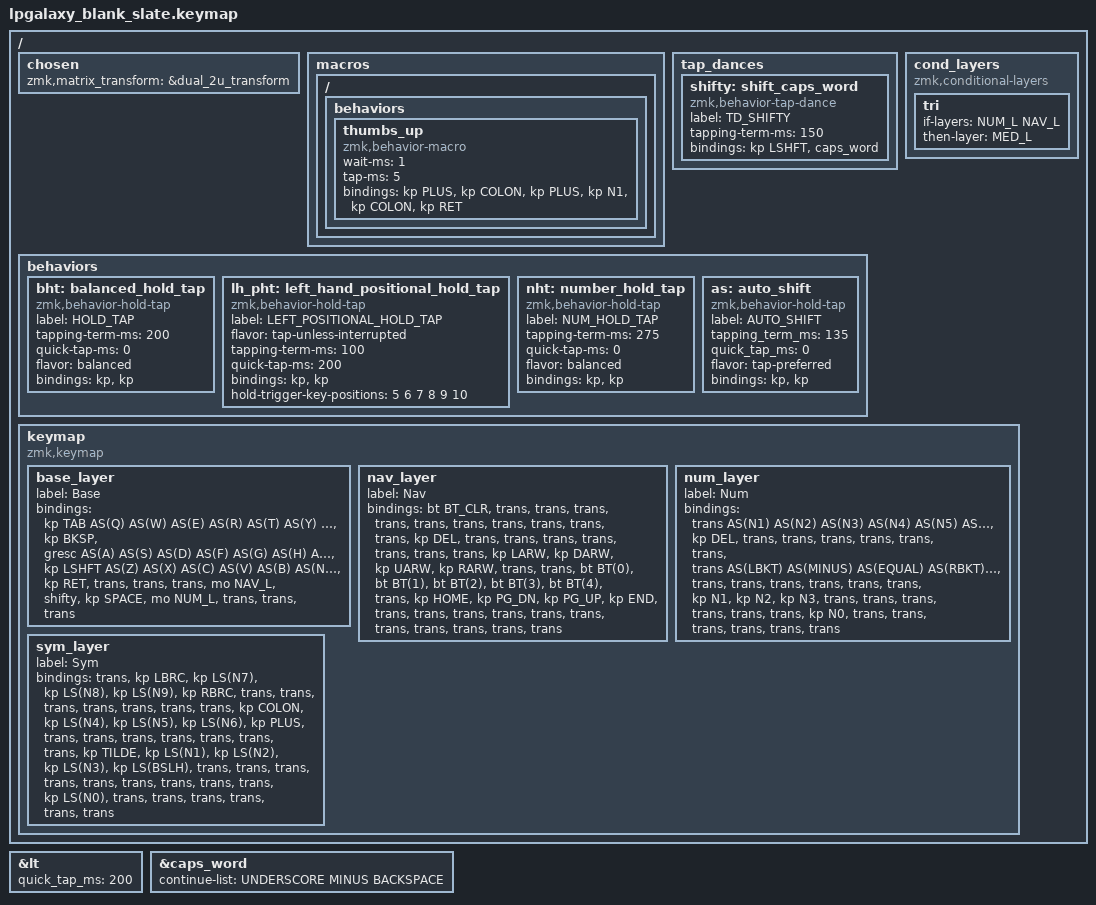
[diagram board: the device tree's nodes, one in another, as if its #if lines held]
/*
 * Copyright (c) 2022 Pete Johanson
 *
 * SPDX-License-Identifier: MIT
 */

#include <behaviors.dtsi>
#include <dt-bindings/zmk/keys.h>
#include <dt-bindings/zmk/bt.h>
#include <dt-bindings/zmk/outputs.h>

#define QWERTY_BASE 1

// #define TBLE_ORTHO   1
#define TBLE_MIT     1
// #define TBLE_DUAL_2U 1

#define NAV_L 1
#define NUM_L 2
#define MED_L 3
#define FUN_L 4

// Using layer taps on thumbs, having quick tap as well helps w/ repeating space/backspace
&lt { quick_tap_ms = <200>; };

#define BT(n) BT_SEL n

#define AS(keycode) &as LS(keycode) keycode

&caps_word {
        continue-list = <UNDERSCORE MINUS BACKSPACE>;
    };

/ {
    chosen {
       zmk,matrix_transform =
#ifdef TBLE_DUAL_2U
                       &dual_2u_transform;
#elif defined(TBLE_MIT)
                       &mit_transform; 
#else
                       &ortho_transform;
#endif
    };

    macros {
      ZMK_MACRO(thumbs_up,
		wait-ms = <1>;
		tap-ms = <5>;
                bindings = <&kp PLUS &kp COLON &kp PLUS &kp N1 &kp COLON &kp RET>;
		)
    };
    
    tap_dances {
    	shifty: shift_caps_word {
		compatible = "zmk,behavior-tap-dance";
		label = "TD_SHIFTY";
		#binding-cells = <0>;
		tapping-term-ms = <150>;
		bindings = <&kp LSHFT>, <&caps_word>;
	};
    };

    cond_layers {
        compatible = "zmk,conditional-layers";
	tri {
	    if-layers = <NUM_L NAV_L>;
	    then-layer = <MED_L>;
        };
    };

    behaviors {

        bht: balanced_hold_tap {
            compatible = "zmk,behavior-hold-tap";
            label = "HOLD_TAP";
            #binding-cells = <2>;
            tapping-term-ms = <200>;    // <---[[moderate duration]]
            quick-tap-ms = <0>;
            flavor = "balanced";
            bindings = <&kp>, <&kp>;
        };

        lh_pht: left_hand_positional_hold_tap {
            compatible = "zmk,behavior-hold-tap";
            label = "LEFT_POSITIONAL_HOLD_TAP";
            #binding-cells = <2>;
            flavor = "tap-unless-interrupted";
            tapping-term-ms = <100>;                        // <---[[produces tap if held longer than tapping-term-ms]]
            quick-tap-ms = <200>;
            bindings = <&kp>, <&kp>;
            hold-trigger-key-positions = <5 6 7 8 9 10>;    // <---[[right-hand keys]]
        };

        nht: number_hold_tap {
            compatible = "zmk,behavior-hold-tap";
            label = "NUM_HOLD_TAP";
            #binding-cells = <2>;
            tapping-term-ms = <275>;    // <---[[slightly higher than moderate duration]]
            quick-tap-ms = <0>;
            flavor = "balanced";
            bindings = <&kp>, <&kp>;
        };

        as: auto_shift {
            compatible = "zmk,behavior-hold-tap";
            label = "AUTO_SHIFT";
            #binding-cells = <2>;
            tapping_term_ms = <135>;
            quick_tap_ms = <0>;
            flavor = "tap-preferred";
            bindings = <&kp>, <&kp>;
        };
    };

    keymap {
        compatible = "zmk,keymap";

        base_layer {
            label = "Base";
            bindings = <
#ifdef QWERTY_BASE
 &kp TAB    AS(Q)      AS(W)      AS(E)       AS(R)          AS(T)          AS(Y)            AS(U)         AS(I)       AS(O)      AS(P)         &kp BKSP
 &gresc     AS(A)      AS(S)      AS(D)       AS(F)          AS(G)          AS(H)            AS(J)         AS(K)       AS(L)      AS(SEMI)      AS(QUOT)
 &kp LSHFT  AS(Z)      AS(X)      AS(C)       AS(V)          AS(B)          AS(N)            AS(M)         AS(COMMA)   AS(DOT)    AS(FSLH)      &kp RET
#else
  &kp Q      &kp W      &kp F       &kp P          &kp B   &none &none  &kp J            &kp L          &kp U       &kp Y      &kp QUOT
  &kp A      &kp R      &kp S       &kp T          &kp G   &none &none  &kp M            &kp N          &kp E       &kp I      &kp O
  &kp Z      &kp X      &kp C       &kp D          &kp V   &none &none  &kp K            &kp H          &kp COMMA   &kp DOT    &kp SEMI
#endif
#ifdef TBLE_DUAL_2U
&trans         &trans &trans    &mo NAV_L      &shifty      &kp SPACE        &mo NUM_L     &trans &trans &trans
#elif defined(TBLE_MIT)
&trans &kp LCTRL &kp LALT  &kp LGUI    &lt NAV_L SPACE          &shifty                   &lt NUM_L SPACE &kp LARW &kp DARW &kp UARW &kp RARW
#else
 &trans &trans         &kp LCTRL  &kp LALT    &mo NAV_L      &shifty      &kp SPACE        &mo NUM_L      &kp RALT    &kp RCTRL          &trans &trans
#endif
            >;
        };

        nav_layer {
            label = "Nav";
            bindings = <
&bt BT_CLR &trans     &trans     &trans      &trans          &trans       &trans     &trans         &trans      &trans     &trans     &kp DEL
&trans     &trans     &trans     &trans      &trans          &trans       &trans     &kp LARW       &kp DARW    &kp UARW   &kp RARW   &trans
&trans     &bt BT(0)  &bt BT(1)  &bt BT(2)   &bt BT(3)       &bt BT(4)    &trans     &kp HOME       &kp PG_DN   &kp PG_UP  &kp END    &trans
#ifdef TBLE_DUAL_2U
&trans  &trans        &trans     &trans              &trans                    &trans       &trans         &trans &trans &trans
#elif defined(TBLE_MIT)
&trans  &trans        &trans     &trans      &trans                &trans             &trans      &trans   &trans &trans &trans
#else
&trans  &trans        &trans     &trans      &trans          &trans       &trans    &trans  &trans         &trans &trans &trans
#endif
            >;
        };

        num_layer {
            label = "Num";
            bindings = <
&trans     AS(N1)   AS(N2)  AS(N3)  AS(N4) AS(N5)      AS(N6)        AS(N7)     AS(N8)      AS(N9)       AS(N0)     &kp DEL
&trans     &trans   &trans  &trans  &trans &trans      &trans        AS(LBKT)   AS(MINUS)   AS(EQUAL)   AS(RBKT)   AS(BSLH)
&trans     &trans   &trans  &trans  &trans &trans      &kp N1        &kp N2     &kp N3      &trans       &trans     &trans
#ifdef TBLE_DUAL_2U
&trans  &trans       &trans     &kp N0              &trans                 &trans            &trans         &trans &trans &trans
#elif defined(TBLE_MIT)
&trans  &trans       &trans     &kp N0      &trans           &none            &trans        &kp DEL      &trans &trans &trans
#else
&trans  &trans       &trans     &kp N0      &trans    &none         &none     &kp ESC        &kp DEL      &trans &trans &trans
#endif
            >;
        };

        sym_layer {
            label = "Sym";
            bindings = <
&trans     &kp LBRC   &kp LS(N7) &kp LS(N8)  &kp LS(N9)   &kp RBRC     &trans     &trans    &trans       &trans       &trans     &trans
&trans     &kp COLON  &kp LS(N4) &kp LS(N5)  &kp LS(N6)   &kp PLUS     &trans     &trans    &trans       &trans       &trans     &trans
&trans     &kp TILDE  &kp LS(N1) &kp LS(N2)  &kp LS(N3)   &kp LS(BSLH) &trans     &trans    &trans       &trans       &trans     &trans
#ifdef TBLE_DUAL_2U
&trans &trans        &trans     &kp LS(N0)              &trans                    &trans       &trans         &trans &trans &trans
#elif defined(TBLE_MIT)
&trans &trans        &trans     &kp LS(N0)      &trans                &trans             &trans      &trans   &trans &trans &trans
#else
&trans &trans        &trans     &kp LS(N0)      &trans          &trans       &trans    &trans  &trans         &trans &trans &trans
#endif
            >;
        };


    };
};

